# FLASHCTL_1.0 register map
Vendor: Texas Instruments
Peripheral module from a debugger description file (folder mspm0l122x_l222x).
Registers are 32-bit, read-write, no defined reset value unless marked. A register's access mark holds for its fields unless they carry their own. Offsets are as the file gives them; lines under a group give offsets from that group; [hi:lo] are bit positions; {n}, {i} and the like mark numbered series; 'fields as' and 'values as' point back to an identical list; <NAME> marks a mode.

## FLASHCTL
0x1020 FLASHCTL_IIDX ro — Interrupt Index Register
  [0] STAT — Indicates which interrupt has fired. 0x0 means no event pending. The priority order is fixed. On each read, only one interrupt is indicated. On a read, the current interrupt (highest priority) is automatically cleared by the hardware and the corresponding interrupt flags in the RIS and MIS are cleared as well. After a read from the CPU (not from the debug interface), the register must be updated with the next highest priority interrupt.
    0=NO_INTR (No Interrupt Pending); 1=DONE (DONE Interrupt Pending)
0x1028 FLASHCTL_IMASK — Interrupt Mask Register
  [0] DONE — Interrupt mask for DONE: 0: Interrupt is disabled in MIS register 1: Interrupt is enabled in MIS register
    0=DISABLED (Interrupt is masked out); 1=ENABLED (Interrupt will request an interrupt service routine and corresponding bit in [IPSTANDARD.MIS] will be set)
0x1030 FLASHCTL_RIS ro — Raw Interrupt Status Register
  [0] DONE — Flash wrapper operation completed. This interrupt bit is set by firmware or the corresponding bit in the ISET register. It is cleared by the corresponding bit in in the ICLR register or reading the IIDX register when this interrupt is the highest priority.
    0=CLR (Interrupt did not occur); 1=SET (Interrupt occurred)
0x1038 FLASHCTL_MIS ro — Masked Interrupt Status Register
  [0] DONE — Flash wrapper operation completed. This masked interrupt bit reflects the bitwise AND of the corresponding RIS and IMASK bits.
    0=CLR (Masked interrupt did not occur); 1=SET (Masked interrupt occurred)
0x1040 FLASHCTL_ISET — Interrupt Set Register
  [0] DONE — 0: No effect 1: Set the DONE interrupt in the RIS register
    0=NO_EFFECT (Writing a 0 has no effect); 1=SET (Set [IPSTANDARD.RIS] bit)
0x1048 FLASHCTL_ICLR — Interrupt Clear Register
  [0] DONE — 0: No effect 1: Clear the DONE interrupt in the RIS register
    0=NO_EFFECT (Writing a 0 has no effect); 1=CLR (Clear [IPSTANDARD.RIS] bit)
0x10E0 FLASHCTL_EVT_MODE ro — Event Mode
  [1:0] INT0_CFG — Event line mode select for peripheral event
    0=DISABLE (The interrupt or event line is disabled.); 1=SOFTWARE (The interrupt or event line is in software mode. Software must clear the RIS.); 2=HARDWARE (The interrupt or event line is in hardware mode. Hardware must clear the RIS.)
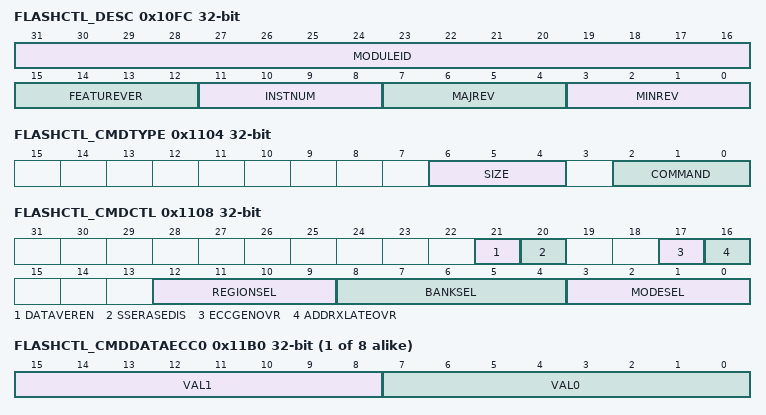
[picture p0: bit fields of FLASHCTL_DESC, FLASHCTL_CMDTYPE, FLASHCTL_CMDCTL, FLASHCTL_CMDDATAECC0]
0x10FC FLASHCTL_DESC ro — Hardware Version Description Register
  [31:16] MODULEID
    0=MINIMUM (Smallest value); 0xFFFF=MAXIMUM (Highest possible value)
  [15:12] FEATUREVER — Feature set
    0=MINIMUM (Minimum Value); 15=MAXIMUM (Maximum Value)
  [11:8] INSTNUM — Instance number
    0=MINIMUM (Smallest value); 15=MAXIMUM (Highest possible value)
  [7:4] MAJREV — Major Revision
    values as INSTNUM
  [3:0] MINREV — Minor Revision
    values as INSTNUM
0x1100 FLASHCTL_CMDEXEC — Command Execute Register
  [0] VAL — Command Execute value Initiates execution of the command specified in the CMDTYPE register.
    0=NOEXECUTE (Command will not execute or is not executing in flash wrapper); 1=EXECUTE (Command will execute or is executing in flash wrapper)
0x1104 FLASHCTL_CMDTYPE — Command Type Register
  [6:4] SIZE — Command size
    0=ONEWORD (Operate on 1 flash word); 1=TWOWORD (Operate on 2 flash words); 2=FOURWORD (Operate on 4 flash words); 3=EIGHTWORD (Operate on 8 flash words); 4=SECTOR (Operate on a flash sector); 5=BANK (Operate on an entire flash bank)
  [2:0] COMMAND — Command type
    0=NOOP (No Operation); 1=PROGRAM; 2=ERASE; 3=READVERIFY (Read Verify - Perform a standalone read verify operation.); 4=MODECHANGE (Mode Change - Perform a mode change only, no other operation.); 5=CLEARSTATUS (Clear Status - Clear status bits in FW_SMSTAT only.); 6=BLANKVERIFY (Blank Verify - Check whether a flash word is in the erased state. This command may only be used with CMDTYPE.SIZE = ONEWORD)
0x1108 FLASHCTL_CMDCTL — Command Control Register
  [21] DATAVEREN — Enable invalid data verify. This checks for 0->1 transitions in the memory when a program operation is initiated. If such a transition is found, the program will fail with an error without executing the program.
    0=DISABLE; 1=ENABLE
  [20] SSERASEDIS — Disable Stair-Step Erase. If set, the default VHV trim voltage setting will be used for all erase pulses. By default, this bit is reset, meaning that the VHV voltage will be stepped during successive erase pulses. The step count, step voltage, begin and end voltages are all hard-wired.
    0=ENABLE; 1=DISABLE
  [17] ECCGENOVR — Override hardware generation of ECC data for program. Use data written to CMDDATAECC*.
    0=NOOVERRIDE (Do not override); 1=OVERRIDE
  [16] ADDRXLATEOVR — Override hardware address translation of address in CMDADDR from a system address to a bank address and bank ID. Use data written to CMDADDR directly as the bank address. Use the value written to CMDCTL.BANKSEL directly as the bank ID. Use the value written to CMDCTL.REGIONSEL directly as the region ID.
    0=NOOVERRIDE (Do not override); 1=OVERRIDE
  [12:9] REGIONSEL — Bank Region A specific region ID can be written to this field to indicate to which region an operation is to be applied if CMDCTL.ADDRXLATEOVR is set.
    1=MAIN (Main Region); 2=NONMAIN (Non-Main Region); 4=TRIM (Trim Region); 8=ENGR (Engr Region)
  [8:4] BANKSEL — Bank Select A specific Bank ID can be written to this field to indicate to which bank an operation is to be applied if CMDCTL.ADDRXLATEOVR is set.
    1=BANK0; 2=BANK1; 4=BANK2; 8=BANK3; 16=BANK4
  [3:0] MODESEL — Mode This field is only used for the Mode Change command type. Otherwise, bank and pump modes are set automaticlly through the NW hardware.
    0=READ (Read Mode); 2=RDMARG0 (Read Margin 0 Mode); 4=RDMARG1 (Read Margin 1 Mode); 6=RDMARG0B (Read Margin 0B Mode); 7=RDMARG1B (Read Margin 1B Mode); 9=PGMVER (Program Verify Mode); 10=PGMSW (Program Single Word); 11=ERASEVER (Erase Verify Mode); 12=ERASESECT (Erase Sector); 14=PGMMW (Program Multiple Word); 15=ERASEBNK (Erase Bank)
0x1120 FLASHCTL_CMDADDR — Command Address Register
  [31:0] VAL — Address value
    0=MINIMUM (Minimum value of [VAL]); 0xFFFFFFFF=MAXIMUM (Maximum value of [VAL])
0x1124 FLASHCTL_CMDBYTEN — Command Program Byte Enable Register
  [17:0] VAL — Command Byte Enable value. A 1-bit per flash word byte value is placed in this register.
    0=MINIMUM (Minimum value of [VAL]); 0x3FFFF=MAXIMUM (Maximum value of [VAL])
0x112C FLASHCTL_CMDDATAINDEX — Command Data Index Register
  [2:0] VAL — Data register index
    0=MINIMUM (Minimum value of [VAL]); 7=MAXIMUM (Maximum value of [VAL])
{0x1130+4i} FLASHCTL_CMDDATA{i} (i=0..2) — Command Data Register {i}
  [31:0] VAL — A 32-bit data value is placed in this field.
    values as FLASHCTL_CMDADDR.VAL
0x113C FLASHCTL_CMDDATA3 — Command Data Register Bits 127:96
  fields as FLASHCTL_CMDDATA0
0x1140 FLASHCTL_CMDDATA4 — Command Data Register 4
  [31:0] VAL — A 32-bit data value is placed in this field. T
    values as FLASHCTL_CMDADDR.VAL
{0x1130+4i} FLASHCTL_CMDDATA{i} (i=5..31) — Command Data Register {i}
  fields as FLASHCTL_CMDDATA0
{0x11B0+4i} FLASHCTL_CMDDATAECC{i} (i=0..7) — Command Data Register ECC {i}
  [15:8] VAL1 — ECC data for bits 127:64 of the data is placed here.
    0=MINIMUM (Minimum value); 255=MAXIMUM (Maximum value)
  [7:0] VAL0 — ECC data for bits 63:0 of the data is placed here.
    0=MINIMUM (Minimum value); 255=MAXIMUM (Maximum value)
0x11D0 FLASHCTL_CMDWEPROTA — Command Write Erase Protect A Register
  [31:0] VAL — Each bit protects 1 sector. bit [0]: When 1, sector 0 of the flash memory will be protected from program and erase. bit [1]: When 1, sector 1 of the flash memory will be protected from program and erase. : : bit [31]: When 1, sector 31 of the flash memory will be protected from program and erase.
    values as FLASHCTL_CMDADDR.VAL
0x11D4 FLASHCTL_CMDWEPROTB — Command Write Erase Protect B Register
  [31:0] VAL — Each bit protects a group of 8 sectors. When a bit is 1, the associated 8 sectors in the flash will be protected from program and erase. A maximum of 256 sectors can be protected with this register.
    values as FLASHCTL_CMDADDR.VAL
0x11D8 FLASHCTL_CMDWEPROTC — Command Write Erase Protect C Register
  [31:0] VAL — Each bit protects a group of 8 sectors. When a bit is 1, the associated 8 sectors in the flash will be protected from program and erase. Note that the sectors protected with this register start at sector 256 in the flash, where the sectors protected by the CMDWEPROTB register end.
    values as FLASHCTL_CMDADDR.VAL
0x1210 FLASHCTL_CMDWEPROTNM — Command Write Erase Protect Non-Main Register
  [31:0] VAL — Each bit protects 1 sector. bit [0]: When 1, sector 0 of the non-main region will be protected from program and erase. bit [1]: When 1, sector 1 of the non-main region will be protected from program and erase. : : bit [31]: When 1, sector 31 of the non-main will be protected from program and erase.
    values as FLASHCTL_CMDADDR.VAL
0x1214 FLASHCTL_CMDWEPROTTR — Command Write Erase Protect Trim Register
  [31:0] VAL — Each bit protects 1 sector. bit [0]: When 1, sector 0 of the engr region will be protected from program and erase. bit [1]: When 1, sector 1 of the engr region will be protected from program and erase. : : bit [31]: When 1, sector 31 of the engr region will be protected from program and erase.
    values as FLASHCTL_CMDADDR.VAL
0x1218 FLASHCTL_CMDWEPROTEN — Command Write Erase Protect Engr Register
  fields as FLASHCTL_CMDWEPROTTR
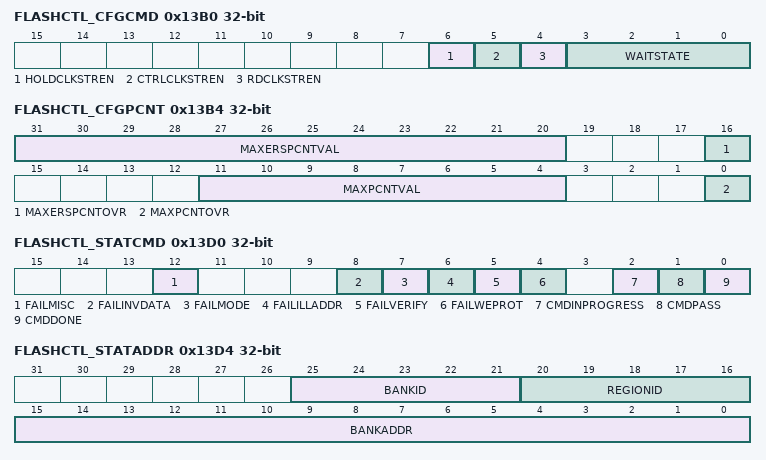
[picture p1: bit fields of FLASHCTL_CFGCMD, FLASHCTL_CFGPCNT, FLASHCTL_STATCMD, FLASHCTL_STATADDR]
0x13B0 FLASHCTL_CFGCMD — Command Configuration Register
  [6] HOLDCLKSTREN — Enable pulse stretching for the clocking of the hold latches for inputs to the flash bank. This effectively divides the flash controller internal clock in order to create a 50/50 duty cycle clock for hold latching.
    0=DISABLE; 1=ENABLE
  [5] CTRLCLKSTREN — Enable pulse stretching when generating a control clock to the flash bank from the flash wrapper. This effectively divides the control clock driven to the bank in order to avoid minimum pulse width requirements at the bank.
    0=DISABLE; 1=ENABLE
  [4] RDCLKSTREN — Enable pulse stretching when generating a read clock to the flash bank from the flash wrapper. This effectively divides the read clock driven to the bank in order to avoid minimum pulse width requirements at the bank.
    0=DISABLE; 1=ENABLE
  [3:0] WAITSTATE — Wait State setting for program verify, erase verify and read verify
    0=MINIMUM (Minimum value); 15=MAXIMUM (Maximum value)
0x13B4 FLASHCTL_CFGPCNT — Pulse Counter Configuration Register
  [31:20] MAXERSPCNTVAL — Override maximum pulse count for erase with this value. If MAXERSPCNTOVR = 0, then this field is ignored. If MAXERSPCNTOVR = 1, then this value will be used to override the max pulse count for erase.
    0=MINIMUM (Minimum value); 0xFFF=MAXIMUM (Maximum value)
  [16] MAXERSPCNTOVR — Override hard-wired maximum pulse count for erase. If set, then the value in MAXERSPCNTVAL will be used as the max pulse count for erase operations. By default, this bit is 0, and a hard-wired max pulse count is used.
    0=DEFAULT (Use hard-wired (default) value for maximum pulse count); 1=OVERRIDE (Use value from MAXERSPCNTVAL field as maximum erase pulse count)
  [11:4] MAXPCNTVAL — Override maximum pulse counter with this value. If MAXPCNTOVR = 0, then this field is ignored. If MAXPCNTOVR = 1 and MAXERSPCNTOVR = 0, then this value will be used to override the max pulse count for both program and erase. Full max value will be {4'h0, MAXPCNTVAL} . If MAXPCNTOVR = 1 and MAXERSPCNTOVR = 1, then this value will be used to override the max pulse count for program only. Full max value will be {4'h0, MAXPCNTVAL}.
    0=MINIMUM (Minimum value); 255=MAXIMUM (Maximum value)
  [0] MAXPCNTOVR — Override hard-wired maximum pulse count. If MAXERSPCNTOVR is not set, then setting this value alone will override the max pulse count for both program and erase. If MAXERSPCNTOVR is set, then this bit will only control the max pulse count setting for program. By default, this bit is 0, and a hard-wired max pulse count is used.
    0=DEFAULT (Use hard-wired (default) value for maximum pulse count); 1=OVERRIDE (Use value from MAXPCNTVAL field as maximum puse count)
0x13D0 FLASHCTL_STATCMD ro — Command Status Register
  [12] FAILMISC — Command failed due to error other than write/erase protect violation or verify error. This is an extra bit in case a new failure mechanism is added which requires a status bit.
    0=STATNOFAIL (No Fail); 1=STATFAIL (Fail)
  [8] FAILINVDATA — Program command failed because an attempt was made to program a stored 0 value to a 1.
    0=STATNOFAIL (No Fail); 1=STATFAIL (Fail)
  [7] FAILMODE — Command failed because a bank has been set to a mode other than READ. Program and Erase commands cannot be initiated unless all banks are in READ mode.
    0=STATNOFAIL (No Fail); 1=STATFAIL (Fail)
  [6] FAILILLADDR — Command failed due to the use of an illegal address
    0=STATNOFAIL (No Fail); 1=STATFAIL (Fail)
  [5] FAILVERIFY — Command failed due to verify error
    0=STATNOFAIL (No Fail); 1=STATFAIL (Fail)
  [4] FAILWEPROT — Command failed due to Write/Erase Protect Sector Violation
    0=STATNOFAIL (No Fail); 1=STATFAIL (Fail)
  [2] CMDINPROGRESS — Command In Progress
    0=STATCOMPLETE (Complete); 1=STATINPROGRESS (In Progress)
  [1] CMDPASS — Command Pass - valid when CMD_DONE field is 1
    0=STATFAIL (Fail); 1=STATPASS (Pass)
  [0] CMDDONE — Command Done
    0=STATNOTDONE (Not Done); 1=STATDONE (Done)
0x13D4 FLASHCTL_STATADDR ro — Address Status Register
  [25:21] BANKID — Current Bank ID A bank indicator is stored in this register which represents the current bank on which the state machine is operating. There is 1 bit per bank.
    1=BANK0; 2=BANK1; 4=BANK2; 8=BANK3; 16=BANK4
  [20:16] REGIONID — Current Region ID A region indicator is stored in this register which represents the current flash region on which the state machine is operating.
    values as FLASHCTL_CMDCTL.REGIONSEL
  [15:0] BANKADDR — Current Bank Address A bank offset address is stored in this register.
    0=MINIMUM (Minimum value); 0xFFFF=MAXIMUM (Maximum value)
0x13D8 FLASHCTL_STATPCNT ro — Pulse Count Status Register
  [11:0] PULSECNT — Current Pulse Counter Value
    0=MINIMUM (Minimum value); 0xFFF=MAXIMUM (Maximum value)
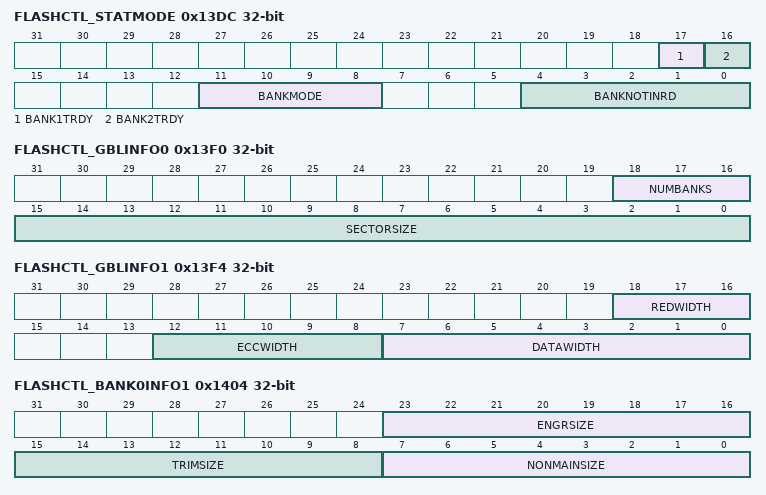
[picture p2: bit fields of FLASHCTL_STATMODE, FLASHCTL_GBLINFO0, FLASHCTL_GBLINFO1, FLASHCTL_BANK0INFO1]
0x13DC FLASHCTL_STATMODE ro — Mode Status Register
  [17] BANK1TRDY — Bank 1T Ready. Bank(s) are ready for 1T access. This is accomplished when the bank and pump have been trimmed.
    0=FALSE (Not ready); 1=TRUE (Ready)
  [16] BANK2TRDY — Bank 2T Ready. Bank(s) are ready for 2T access. This is accomplished when the pump has fully driven power rails to the bank(s).
    0=FALSE (Not ready); 1=TRUE (Ready)
  [11:8] BANKMODE — Indicates mode of bank(s) that are not in READ mode
    values as FLASHCTL_CMDCTL.MODESEL
  [4:0] BANKNOTINRD — Bank not in read mode. Indicates which banks are not in READ mode. There is 1 bit per bank.
    1=BANK0; 2=BANK1; 4=BANK2; 8=BANK3; 16=BANK4
0x13F0 FLASHCTL_GBLINFO0 ro — Global Information Register 0
  [18:16] NUMBANKS — Number of banks instantiated Minimum: 1 Maximum: 5
    1=MINIMUM (Minimum value); 5=MAXIMUM (Maximum value)
  [15:0] SECTORSIZE — Sector size in bytes
    0x400=ONEKB (Sector size is ONEKB); 0x800=TWOKB (Sector size is TWOKB)
0x13F4 FLASHCTL_GBLINFO1 ro — Global Information Register 1
  [18:16] REDWIDTH — Redundant data width in bits
    0=W0BIT (Redundant data width is 0. Redundancy/Repair not present.); 2=W2BIT (Redundant data width is 2 bits); 4=W4BIT (Redundant data width is 4 bits)
  [12:8] ECCWIDTH — ECC data width in bits
    0=W0BIT (ECC data width is 0. ECC not used.); 8=W8BIT (ECC data width is 8 bits); 16=W16BIT (ECC data width is 16 bits)
  [7:0] DATAWIDTH — Data width in bits
    64=W64BIT (Data width is 64 bits); 128=W128BIT (Data width is 128 bits)
0x13F8 FLASHCTL_GBLINFO2 ro — Global Information Register 2
  [3:0] DATAREGISTERS — Number of data registers present.
    1=MINIMUM (Minimum value of [DATAREGISTERS]); 8=MAXIMUM (Maximum value of [DATAREGISTERS])
{0x1400+0x10*i} FLASHCTL_BANK{i}INFO0 ro (i=0..2) — Bank Information Register 0 for Bank {i}
  [11:0] MAINSIZE — Main region size in sectors Minimum: 0x8 (8) Maximum: 0x200 (512)
    8=MINSECTORS (Minimum value of [MAINSIZE]); 0x200=MAXSECTORS (Maximum value of [MAINSIZE])
0x1404 FLASHCTL_BANK0INFO1 ro — Bank Information Register 1 for Bank 0
  [23:16] ENGRSIZE — Engr region size in sectors Minimum: 0x0 (0) Maximum: 0x10 (16)
    0=MINSECTORS (Minimum value of [ENGRSIZE]); 32=MAXSECTORS (Maximum value of [ENGRSIZE])
  [15:8] TRIMSIZE — Trim region size in sectors Minimum: 0x0 (0) Maximum: 0x10 (16)
    0=MINSECTORS (Minimum value of [TRIMSIZE]); 32=MAXSECTORS (Maximum value of [TRIMSIZE])
  [7:0] NONMAINSIZE — Non-main region size in sectors Minimum: 0x0 (0) Maximum: 0x10 (16)
    0=MINSECTORS (Minimum value of [NONMAINSIZE]); 32=MAXSECTORS (Maximum value of [NONMAINSIZE])
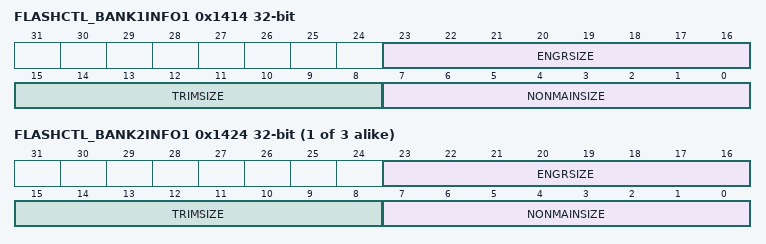
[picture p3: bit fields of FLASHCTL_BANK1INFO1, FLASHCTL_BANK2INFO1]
0x1414 FLASHCTL_BANK1INFO1 ro — Bank Information Register 1 for Bank 1
  [23:16] ENGRSIZE — Engr region size in sectors Minimum: 0x0 (0) Maximum: 0x10 (16)
    values as FLASHCTL_BANK0INFO1.ENGRSIZE
  [15:8] TRIMSIZE — Trim region size in sectors
    values as FLASHCTL_BANK0INFO1.TRIMSIZE
  [7:0] NONMAINSIZE — Non-main region size in sectors
    values as FLASHCTL_BANK0INFO1.NONMAINSIZE
{0x1404+0x10*i} FLASHCTL_BANK{i}INFO1 ro (i=2..4) — Bank Information Register 1 for Bank {i}
  [23:16] ENGRSIZE — Engr region size in sectors
    values as FLASHCTL_BANK0INFO1.ENGRSIZE
  [15:8] TRIMSIZE — Trim region size in sectors
    values as FLASHCTL_BANK0INFO1.TRIMSIZE
  [7:0] NONMAINSIZE — Non-main region size in sectors
    values as FLASHCTL_BANK0INFO1.NONMAINSIZE
0x1430 FLASHCTL_BANK3INFO0 ro — Bank Information Register 0 for Bank 3
  [11:0] MAINSIZE — Main region size in sectors
    values as FLASHCTL_BANK0INFO0.MAINSIZE
0x1440 FLASHCTL_BANK4INFO0 ro — Bank Information Register 0 for Bank 4
  fields as FLASHCTL_BANK3INFO0
